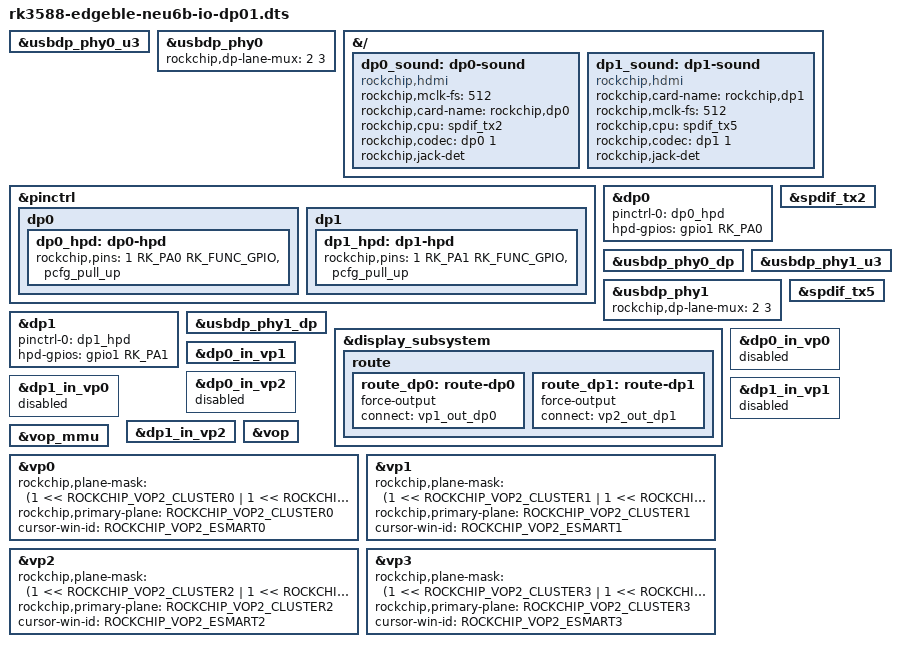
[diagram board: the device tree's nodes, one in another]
// SPDX-License-Identifier: (GPL-2.0+ OR MIT)

/dts-v1/;
/plugin/;

#include <dt-bindings/gpio/gpio.h>
#include <dt-bindings/pinctrl/rockchip.h>
#include <dt-bindings/display/rockchip_vop.h>

/* DP0 */
&usbdp_phy0_u3 {
	status = "okay";
};

&usbdp_phy0 {
	status = "okay";
};

&{/} {
	dp0_sound: dp0-sound {
		status = "okay";
		compatible = "rockchip,hdmi";
		rockchip,mclk-fs = <512>;
		rockchip,card-name= "rockchip,dp0";
		rockchip,cpu = <&spdif_tx2>;
		rockchip,codec = <&dp0 1>;
		rockchip,jack-det;
	};
};

&pinctrl {
	dp0 {
		dp0_hpd: dp0-hpd {
			rockchip,pins = <1 RK_PA0 RK_FUNC_GPIO &pcfg_pull_up>;
		};
	};
};

&dp0 {
	status = "okay";
	pinctrl-names = "default";
	pinctrl-0 = <&dp0_hpd>;
	hpd-gpios = <&gpio1 RK_PA0 GPIO_ACTIVE_HIGH>; /* DP1_HPDIN_M0 */
};

&spdif_tx2 {
	status = "okay";
};

&usbdp_phy0_dp {
	status = "okay";
};

&usbdp_phy0 {
	status = "okay";
	rockchip,dp-lane-mux = < 2 3 >;
};

/* DP1 */
&usbdp_phy1_u3 {
	status = "okay";
};

&usbdp_phy1 {
	status = "okay";
};

&{/} {
	dp1_sound: dp1-sound {
		status = "okay";
		compatible = "rockchip,hdmi";
		rockchip,card-name= "rockchip,dp1";
		rockchip,mclk-fs = <512>;
		rockchip,cpu = <&spdif_tx5>;
		rockchip,codec = <&dp1 1>;
		rockchip,jack-det;
	};
};

&pinctrl {
	dp1 {
		dp1_hpd: dp1-hpd {
			rockchip,pins = <1 RK_PA1 RK_FUNC_GPIO &pcfg_pull_up>;
		};
	};
};

&dp1 {
	status = "okay";
	pinctrl-names = "default";
	pinctrl-0 = <&dp1_hpd>;
	hpd-gpios = <&gpio1 RK_PA1 GPIO_ACTIVE_HIGH>; /* DP2_HPDIN_M0 */
};

&spdif_tx5 {
	status = "okay";
};

&usbdp_phy1_dp {
	status = "okay";
};

&usbdp_phy1 {
	status = "okay";
	rockchip,dp-lane-mux = < 2 3 >;
};

&display_subsystem {
	route {
		route_dp0: route-dp0 {
			status = "okay";
			force-output;
			connect = <&vp1_out_dp0>;
		};

		route_dp1: route-dp1 {
			status = "okay";
			force-output;
			connect = <&vp2_out_dp1>;
		};
	};
};

&dp0_in_vp0 {
	status = "disabled";
};

&dp0_in_vp1 {
	status = "okay";
};

&dp0_in_vp2 {
	status = "disabled";
};

&dp1_in_vp0 {
	status = "disabled";
};

&dp1_in_vp1 {
	status = "disabled";
};

&dp1_in_vp2 {
	status = "okay";
};

&vop {
	status = "okay";
};

&vop_mmu {
	status = "okay";
};

/* vp0 & vp1 splice for 8K output */
&vp0 {
	rockchip,plane-mask = <(1 << ROCKCHIP_VOP2_CLUSTER0 | 1 << ROCKCHIP_VOP2_ESMART0)>;
	rockchip,primary-plane = <ROCKCHIP_VOP2_CLUSTER0>;
	cursor-win-id = <ROCKCHIP_VOP2_ESMART0>;
};

&vp1 {
	rockchip,plane-mask = <(1 << ROCKCHIP_VOP2_CLUSTER1 | 1 << ROCKCHIP_VOP2_ESMART1)>;
	rockchip,primary-plane = <ROCKCHIP_VOP2_CLUSTER1>;
	cursor-win-id = <ROCKCHIP_VOP2_ESMART1>;
};

&vp2 {
	rockchip,plane-mask = <(1 << ROCKCHIP_VOP2_CLUSTER2 | 1 << ROCKCHIP_VOP2_ESMART2)>;
	rockchip,primary-plane = <ROCKCHIP_VOP2_CLUSTER2>;
	cursor-win-id = <ROCKCHIP_VOP2_ESMART2>;
};

&vp3 {
	rockchip,plane-mask = <(1 << ROCKCHIP_VOP2_CLUSTER3 | 1 << ROCKCHIP_VOP2_ESMART3)>;
	rockchip,primary-plane = <ROCKCHIP_VOP2_CLUSTER3>;
	cursor-win-id = <ROCKCHIP_VOP2_ESMART3>;
};
